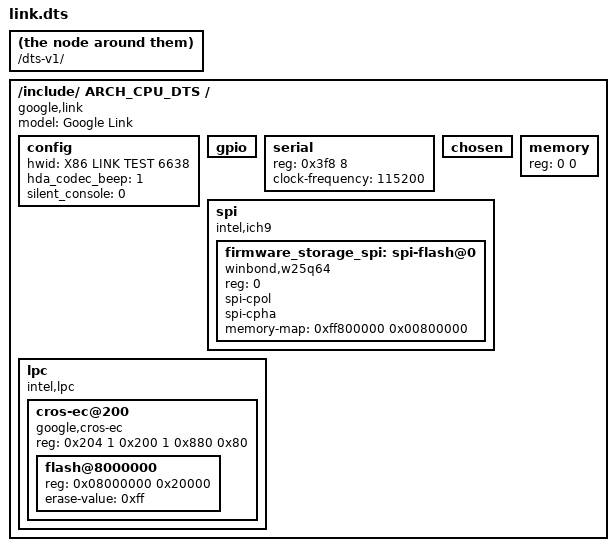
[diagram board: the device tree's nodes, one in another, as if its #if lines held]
/dts-v1/;

/include/ ARCH_CPU_DTS
#ifdef CONFIG_CHROMEOS
/include/ "chromeos-coreboot.dtsi"
/include/ "flashmap-coreboot-8mb_1mb_rom.dtsi"
/include/ "flashmap-coreboot-8mb-ec.dtsi"
#endif

/ {
        #address-cells = <1>;
        #size-cells = <1>;
	model = "Google Link";
	compatible = "google,link", "intel,celeron-ivybridge";

	config {
		hwid = "X86 LINK TEST 6638";
		hda_codec_beep = <1>;
		silent_console = <0>;
	};

        gpio: gpio {};

	serial {
		reg = <0x3f8 8>;
		clock-frequency = <115200>;
	};

        chosen { };
        memory { device_type = "memory"; reg = <0 0>; };

	spi {
		#address-cells = <1>;
		#size-cells = <0>;
		compatible = "intel,ich9";
		firmware_storage_spi: spi-flash@0 {
			reg = <0>;
			spi-cpol;
			spi-cpha;
			compatible = "winbond,w25q64", "spi-flash";
			memory-map = <0xff800000 0x00800000>;
		};
	};

	lpc {
		compatible = "intel,lpc";
		#address-cells = <1>;
		#size-cells = <1>;
		cros-ec@200 {
			compatible = "google,cros-ec";
			reg = <0x204 1 0x200 1 0x880 0x80>;

			/* This describes the flash memory within the EC */
			#address-cells = <1>;
			#size-cells = <1>;
			flash@8000000 {
				reg = <0x08000000 0x20000>;
				erase-value = <0xff>;
			};
		};
	};
};
